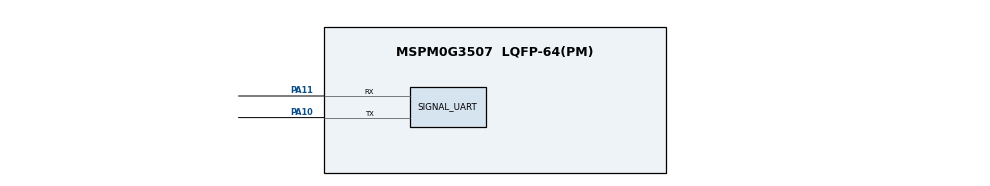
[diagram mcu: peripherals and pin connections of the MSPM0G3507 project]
/** PROFILE_03_DAC_GENERATOR: TIMG6 -> DAC0 FIFO, DMA_CH1, UART0. */
//@cliArgs --device "MSPM0G350X" --package "LQFP-64(PM)" --part "Default"
//@v2CliArgs --device "MSPM0G3507" --package "LQFP-64(PM)"
// @cliArgs --board /ti/boards/LP_MSPM0G3507 --rtos nortos

const ProjectConfig = scripting.addModule("/ti/project_config/ProjectConfig");
const Board = scripting.addModule("/ti/driverlib/Board");
const SYSCTL = scripting.addModule("/ti/driverlib/SYSCTL");
const DAC12 = scripting.addModule("/ti/driverlib/DAC12");
const TIMER = scripting.addModule("/ti/driverlib/TIMER", {}, false);
const DAC_TIMER = TIMER.addInstance();
const UART = scripting.addModule("/ti/driverlib/UART", {}, false);
const SIGNAL_UART = UART.addInstance();

ProjectConfig.genLibCMSIS = true;

const mfpGate = system.clockTree["MFPCLKGATE"];
mfpGate.enable = true;

DAC12.dacConfigureDMA = true;
DAC12.dacFIFOEn = true;
DAC12.dacFIFOThresh = "TWO_QTRS_EMPTY";
DAC12.dacFIFOTrigger = "HWTRIG0";
DAC12.sub0ChanID = 3;
DAC12.dacEnabledInterrupts = ["DMA_DONE"];
DAC12.dacSampleTimerEn = false;
DAC12.dacOutputPinEn = true;
DAC12.dacAmplifier = "ON";
DAC12.DMA_CHANNEL.$name = "SIGNAL_DAC_DMA";
DAC12.DMA_CHANNEL.peripheral.$assign = "DMA_CH1";
DAC12.DMA_CHANNEL.transferMode = "FULL_CH_REPEAT_SINGLE";
DAC12.DMA_CHANNEL.addressMode = "b2f";
DAC12.DMA_CHANNEL.srcLength = "HALF_WORD";
DAC12.DMA_CHANNEL.dstLength = "HALF_WORD";

DAC_TIMER.$name = "SIGNAL_DAC_TIMER";
DAC_TIMER.timerClkSrc = "BUSCLK";
DAC_TIMER.timerPeriod = "10us";
DAC_TIMER.timerMode = "PERIODIC";
DAC_TIMER.event1PublisherChannel = 3;
DAC_TIMER.event1ControllerInterruptEn = ["ZERO_EVENT"];
DAC_TIMER.peripheral.$assign = "TIMG6";

SIGNAL_UART.$name = "SIGNAL_UART";
SIGNAL_UART.profile = "CONFIG_PROFILE_1";
SIGNAL_UART.peripheral.$assign = "UART0";
SIGNAL_UART.uartClkSrc = "BUSCLK";
SIGNAL_UART.targetBaudRate = 115200;
SIGNAL_UART.enableInternalLoopback = false;
SIGNAL_UART.enableFIFO = true;
SIGNAL_UART.peripheral.txPin.$assign = "PA10";
SIGNAL_UART.peripheral.rxPin.$assign = "PA11";

SYSCTL.MFPCLKEn = true;
SYSCTL.forceDefaultClkConfig = true;
SYSCTL.clockTreeEn = true;
